# LPC178x7x register map
File version: 0.9-mod
CPU: CM3 r0p0, little endian, no MPU, no FPU, 3 interrupt priority bits
Registers are 32-bit, read-write, reset 0x0 unless marked. A register's access mark holds for its fields unless they carry their own. Offsets are from the block's base; [hi:lo] are bit positions; {n}, {i} and the like mark numbered series.

## QEI — Quadrature Encoder Interface (QEI)
Base 0x400BC000
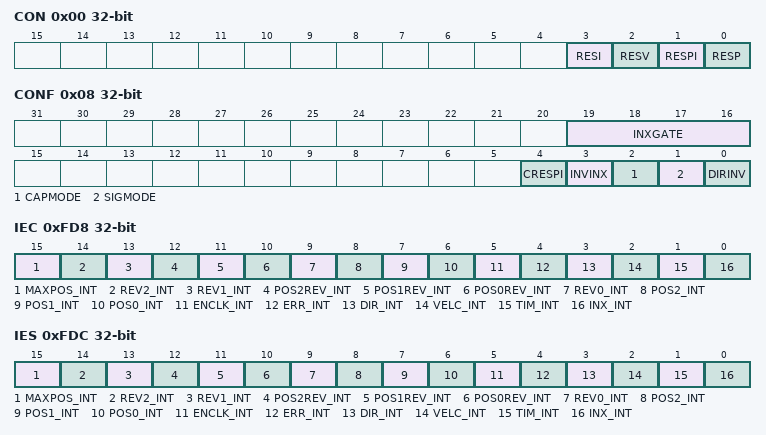
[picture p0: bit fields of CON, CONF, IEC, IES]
0x00 CON wo reset not defined — Control register
  [3] RESI — Reset index counter. When set = 1, resets the index counter to all zeros. Autoclears when the index counter is cleared.
  [2] RESV — Reset velocity. When set = 1, resets the velocity counter to all zeros, reloads the velocity timer, and presets the velocity compare register. Autoclears when the velocity counter is cleared.
  [1] RESPI — Reset position counter on index. When set = 1, resets the position counter to all zeros once only the first time an index pulse occurs. Autoclears when the position counter is cleared.
  [0] RESP — Reset position counter. When set = 1, resets the position counter to all zeros. Autoclears when the position counter is cleared.
0x04 STAT ro — Status register
  [0] DIR — Direction bit. In combination with DIRINV bit indicates forward or reverse direction. See Table 597.
0x08 CONF — Configuration register
  [19:16] INXGATE — Index gating configuration: When INXGATE[16] = 1, pass the index when PHA = 1 and PHB = 0, otherwise block index. When INXGATE[17] = 1, pass the index when PHA = 1 and PHB = 1, otherwise block index. When INXGATE[18] = 1, pass the index when PHA = 0 and PHB = 1, otherwise block index. When INXGATE[19] = 1, pass the index when PHA = 0 and PHB = 0, otherwise block index.
  [4] CRESPI — Continuously reset the position counter on index. When 1, resets the position counter to all zeros whenever an index pulse occurs after the next position increase (recalibration).
  [3] INVINX — Invert Index. When 1, inverts the sense of the index input.
  [2] CAPMODE — Capture Mode. When 0, only PhA edges are counted (2X). When 1, BOTH PhA and PhB edges are counted (4X), increasing resolution but decreasing range.
  [1] SIGMODE — Signal Mode. When 0, PhA and PhB function as quadrature encoder inputs. When 1, PhA functions as the direction signal and PhB functions as the clock signal.
  [0] DIRINV — Direction invert. When 1, complements the DIR bit.
0x0C POS ro — Position register
  [31:0] POS — Current position value.
0x10 MAXPOS — Maximum position register
  [31:0] MAXPOS — Current maximum position value.
{0x14+4i} CMPOS{i} reset 0xFFFFFFFF (i=0..2) — Position compare register {i}
  [31:0] PCMP{i} — Position compare value {i}.
0x20 INXCNT ro — Index count register 0
  [31:0] ENCPOS — Current index counter value.
0x24 INXCMP0 reset 0xFFFFFFFF — Index compare register 0
  [31:0] ICMP0 — Index compare value 0.
0x28 LOAD — Velocity timer reload register
  [31:0] VELLOAD — Current velocity timer load value.
0x2C TIME ro — Velocity timer register
  [31:0] VELVAL — Current velocity timer value.
0x30 VEL ro — Velocity counter register
  [31:0] VELPC — Current velocity pulse count.
0x34 CAP ro reset 0xFFFFFFFF — Velocity capture register
  [31:0] VELCAP — Last velocity capture.
0x38 VELCOMP — Velocity compare register
  [31:0] VELPC — Compare velocity pulse count.
0x3C FILTERPHA — Digital filter register on PHA
  [31:0] FILTA — Digital filter sampling delay for PhA.
0x40 FILTERPHB — Digital filter register on PHB
  [31:0] FILTB — Digital filter sampling delay for PhB.
0x44 FILTERINX — Digital filter register on IDX
  [31:0] FITLINX — Digital filter sampling delay for the index.
0x48 WINDOW reset 0xF — Index acceptance window register
  [31:0] WINDOW — Index acceptance window width.
0x4C INXCMP1 reset 0xFFFFFFFF — Index compare register 1
  [31:0] ICMP1 — Index compare value 1.
0x50 INXCMP2 reset 0xFFFFFFFF — Index compare register 2
  [31:0] ICMP2 — Index compare value 2.
0xFD8 IEC wo reset not defined — Interrupt enable clear register
  [15] MAXPOS_INT — Writing a 1 disables the MAXPOS_Int interrupt in the QEIIE register.
  [14] REV2_INT — Writing a 1 disables the REV2_Int interrupt in the QEIIE register.
  [13] REV1_INT — Writing a 1 disables the REV1_Int interrupt in the QEIIE register.
  [12] POS2REV_INT — Writing a 1 disables the POS2REV_Int interrupt in the QEIIE register.
  [11] POS1REV_INT — Writing a 1 disables the POS1REV_Int interrupt in the QEIIE register.
  [10] POS0REV_INT — Writing a 1 disables the POS0REV_Int interrupt in the QEIIE register.
  [9] REV0_INT — Writing a 1 disables the REV0_Int interrupt in the QEIIE register.
  [8] POS2_INT — Writing a 1 disables the POS2_Int interrupt in the QEIIE register.
  [7] POS1_INT — Writing a 1 disables the POS1_Int interrupt in the QEIIE register.
  [6] POS0_INT — Writing a 1 disables the POS0_Int interrupt in the QEIIE register.
  [5] ENCLK_INT — Writing a 1 disables the ENCLK_Int interrupt in the QEIIE register.
  [4] ERR_INT — Writing a 1 disables the ERR_Int interrupt in the QEIIE register.
  [3] DIR_INT — Writing a 1 disables the DIR_Int interrupt in the QEIIE register.
  [2] VELC_INT — Writing a 1 disables the VELC_Int interrupt in the QEIIE register.
  [1] TIM_INT — Writing a 1 disables the TIN_Int interrupt in the QEIIE register.
  [0] INX_INT — Writing a 1 disables the INX_Int interrupt in the QEIIE register.
0xFDC IES wo reset not defined — Interrupt enable set register
  [15] MAXPOS_INT — Writing a 1 enables the MAXPOS_Int interrupt in the QEIIE register.
  [14] REV2_INT — Writing a 1 enables the REV2_Int interrupt in the QEIIE register.
  [13] REV1_INT — Writing a 1 enables the REV1_Int interrupt in the QEIIE register.
  [12] POS2REV_INT — Writing a 1 enables the POS2REV_Int interrupt in the QEIIE register.
  [11] POS1REV_INT — Writing a 1 enables the POS1REV_Int interrupt in the QEIIE register.
  [10] POS0REV_INT — Writing a 1 enables the POS0REV_Int interrupt in the QEIIE register.
  [9] REV0_INT — Writing a 1 enables the REV0_Int interrupt in the QEIIE register.
  [8] POS2_INT — Writing a 1 enables the POS2_Int interrupt in the QEIIE register.
  [7] POS1_INT — Writing a 1 enables the POS1_Int interrupt in the QEIIE register.
  [6] POS0_INT — Writing a 1 enables the POS0_Int interrupt in the QEIIE register.
  [5] ENCLK_INT — Writing a 1 enables the ENCLK_Int interrupt in the QEIIE register.
  [4] ERR_INT — Writing a 1 enables the ERR_Int interrupt in the QEIIE register.
  [3] DIR_INT — Writing a 1 enables the DIR_Int interrupt in the QEIIE register.
  [2] VELC_INT — Writing a 1 enables the VELC_Int interrupt in the QEIIE register.
  [1] TIM_INT — Writing a 1 enables the TIN_Int interrupt in the QEIIE register.
  [0] INX_INT — Writing a 1 enables the INX_Int interrupt in the QEIIE register.
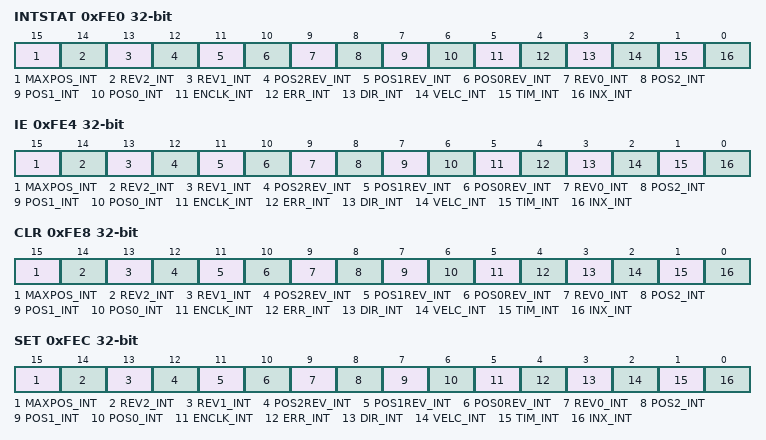
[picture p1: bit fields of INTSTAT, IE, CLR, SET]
0xFE0 INTSTAT ro — Interrupt status register
  [15] MAXPOS_INT — Indicates that the current position count goes through the MAXPOS value to zero in the forward direction, or through zero to MAXPOS in the reverse direction.
  [14] REV2_INT — Indicates that the index compare 2 value is equal to the current index count.
  [13] REV1_INT — Indicates that the index compare 1value is equal to the current index count.
  [12] POS2REV_INT — Combined position 2 and revolution count interrupt. Set when both the POS2_Int bit is set and the REV2_Int is set.
  [11] POS1REV_INT — Combined position 1 and revolution count interrupt. Set when both the POS1_Int bit is set and the REV1_Int is set.
  [10] POS0REV_INT — Combined position 0 and revolution count interrupt. Set when both the POS0_Int bit is set and the REV0_Int is set.
  [9] REV0_INT — Indicates that the index compare 0 value is equal to the current index count.
  [8] POS2_INT — Indicates that the position 2 compare value is equal to the current position.
  [7] POS1_INT — Indicates that the position 1compare value is equal to the current position.
  [6] POS0_INT — Indicates that the position 0 compare value is equal to the current position.
  [5] ENCLK_INT — Indicates that and encoder clock pulse was detected.
  [4] ERR_INT — Indicates that an encoder phase error was detected.
  [3] DIR_INT — Indicates that a change of direction was detected.
  [2] VELC_INT — Indicates that captured velocity is less than compare velocity.
  [1] TIM_INT — Indicates that a velocity timer overflow occurred
  [0] INX_INT — Indicates that an index pulse was detected.
0xFE4 IE ro — Interrupt enable register
  [15] MAXPOS_INT — When 1, the MAXPOS_Int interrupt is enabled.
  [14] REV2_INT — When 1, the REV2_Int interrupt is enabled.
  [13] REV1_INT — When 1, the REV1_Int interrupt is enabled.
  [12] POS2REV_INT — When 1, the POS2REV_Int interrupt is enabled.
  [11] POS1REV_INT — When 1, the POS1REV_Int interrupt is enabled.
  [10] POS0REV_INT — When 1, the POS0REV_Int interrupt is enabled.
  [9] REV0_INT — When 1, the REV0_Int interrupt is enabled.
  [8] POS2_INT — When 1, the POS2_Int interrupt is enabled.
  [7] POS1_INT — When 1, the POS1_Int interrupt is enabled.
  [6] POS0_INT — When 1, the POS0_Int interrupt is enabled.
  [5] ENCLK_INT — When 1, the ENCLK_Int interrupt is enabled.
  [4] ERR_INT — When 1, the ERR_Int interrupt is enabled.
  [3] DIR_INT — When 1, the DIR_Int interrupt is enabled.
  [2] VELC_INT — When 1, the VELC_Int interrupt is enabled.
  [1] TIM_INT — When 1, the TIN_Int interrupt is enabled.
  [0] INX_INT — When 1, the INX_Int interrupt is enabled.
0xFE8 CLR wo reset not defined — Interrupt status clear register
  [15] MAXPOS_INT — Writing a 1 clears the MAXPOS_Int bit in QEIINTSTAT.
  [14] REV2_INT — Writing a 1 clears the REV2_Int bit in QEIINTSTAT.
  [13] REV1_INT — Writing a 1 clears the REV1_Int bit in QEIINTSTAT.
  [12] POS2REV_INT — Writing a 1 clears the POS2REV_Int bit in QEIINTSTAT.
  [11] POS1REV_INT — Writing a 1 clears the POS1REV_Int bit in QEIINTSTAT.
  [10] POS0REV_INT — Writing a 1 clears the POS0REV_Int bit in QEIINTSTAT.
  [9] REV0_INT — Writing a 1 clears the REV0_Int bit in QEIINTSTAT.
  [8] POS2_INT — Writing a 1 clears the POS2_Int bit in QEIINTSTAT.
  [7] POS1_INT — Writing a 1 clears the POS1_Int bit in QEIINTSTAT.
  [6] POS0_INT — Writing a 1 clears the POS0_Int bit in QEIINTSTAT.
  [5] ENCLK_INT — Writing a 1 clears the ENCLK_Int bit in QEIINTSTAT.
  [4] ERR_INT — Writing a 1 clears the ERR_Int bit in QEIINTSTAT.
  [3] DIR_INT — Writing a 1 clears the DIR_Int bit in QEIINTSTAT.
  [2] VELC_INT — Writing a 1 clears the VELC_Int bit in QEIINTSTAT.
  [1] TIM_INT — Writing a 1 clears the TIN_Int bit in QEIINTSTAT.
  [0] INX_INT — Writing a 1 clears the INX_Int bit in QEIINTSTAT.
0xFEC SET wo reset not defined — Interrupt status set register
  [15] MAXPOS_INT — Writing a 1 sets the MAXPOS_Int bit in QEIINTSTAT.
  [14] REV2_INT — Writing a 1 sets the REV2_Int bit in QEIINTSTAT.
  [13] REV1_INT — Writing a 1 sets the REV1_Int bit in QEIINTSTAT.
  [12] POS2REV_INT — Writing a 1 sets the POS2REV_Int bit in QEIINTSTAT.
  [11] POS1REV_INT — Writing a 1 sets the POS1REV_Int bit in QEIINTSTAT.
  [10] POS0REV_INT — Writing a 1 sets the POS0REV_Int bit in QEIINTSTAT.
  [9] REV0_INT — Writing a 1 sets the REV0_Int bit in QEIINTSTAT.
  [8] POS2_INT — Writing a 1 sets the POS2_Int bit in QEIINTSTAT.
  [7] POS1_INT — Writing a 1 sets the POS1_Int bit in QEIINTSTAT.
  [6] POS0_INT — Writing a 1 sets the POS0_Int bit in QEIINTSTAT.
  [5] ENCLK_INT — Writing a 1 sets the ENCLK_Int bit in QEIINTSTAT.
  [4] ERR_INT — Writing a 1 sets the ERR_Int bit in QEIINTSTAT.
  [3] DIR_INT — Writing a 1 sets the DIR_Int bit in QEIINTSTAT.
  [2] VELC_INT — Writing a 1 sets the VELC_Int bit in QEIINTSTAT.
  [1] TIM_INT — Writing a 1 sets the TIN_Int bit in QEIINTSTAT.
  [0] INX_INT — Writing a 1 sets the INX_Int bit in QEIINTSTAT.
